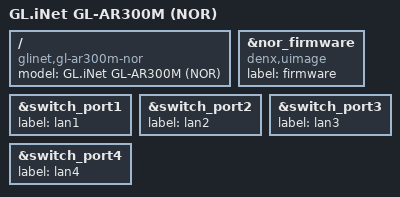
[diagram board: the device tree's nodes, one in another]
#include "qca9531_glinet_gl-ar300m.dtsi"
#include "qca953x_ag71xx.dtsi"
#include "qca953x_dsa.dtsi"

/ {
	compatible = "glinet,gl-ar300m-nor", "qca,qca9531";
	model = "GL.iNet GL-AR300M (NOR)";
};

&nor_firmware {
	compatible = "denx,uimage";
	label = "firmware";
};

&switch_port1 {
	status = "okay";
	label = "lan1";
};

&switch_port2 {
	status = "okay";
	label = "lan2";
};

&switch_port3 {
	status = "okay";
	label = "lan3";
};

&switch_port4 {
	status = "okay";
	label = "lan4";
};
